VERSION "MFE24 Sensor Master v3 (ascii-safe)"

NS_ :

BS_:

BU_: Loadcells Accels FrontNode RearCAN RideHeight VehicleController

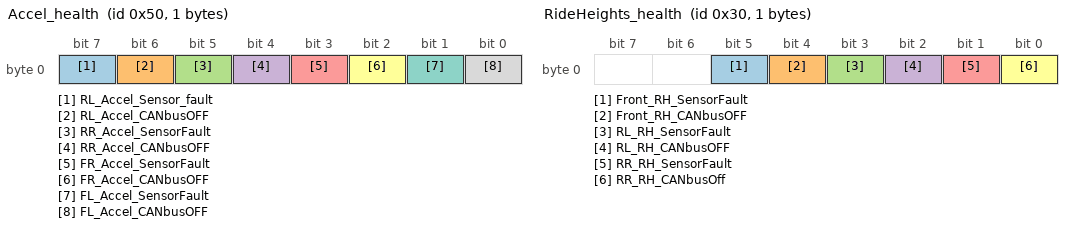
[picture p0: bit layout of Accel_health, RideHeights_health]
BO_ 80 Accel_health: 1 Accels
 SG_ RL_Accel_Sensor_fault : 7|1@1- (1,0) [0|0] "" Vector__XXX
 SG_ RL_Accel_CANbusOFF : 6|1@1- (1,0) [0|0] "" Vector__XXX
 SG_ RR_Accel_SensorFault : 5|1@1- (1,0) [0|0] "" Vector__XXX
 SG_ RR_Accel_CANbusOFF : 4|1@1- (1,0) [0|0] "" Vector__XXX
 SG_ FR_Accel_SensorFault : 3|1@1- (1,0) [0|0] "" Vector__XXX
 SG_ FR_Accel_CANbusOFF : 2|1@1- (1,0) [0|0] "" Vector__XXX
 SG_ FL_Accel_SensorFault : 1|1@1- (1,0) [0|0] "" Vector__XXX
 SG_ FL_Accel_CANbusOFF : 0|1@1- (1,0) [0|0] "" Vector__XXX

BO_ 48 RideHeights_health: 1 RideHeight
 SG_ Front_RH_SensorFault : 5|1@1- (1,0) [0|0] "" Vector__XXX
 SG_ Front_RH_CANbusOFF : 4|1@1- (1,0) [0|0] "" Vector__XXX
 SG_ RL_RH_SensorFault : 3|1@1- (1,0) [0|0] "" Vector__XXX
 SG_ RL_RH_CANbusOFF : 2|1@1- (1,0) [0|0] "" Vector__XXX
 SG_ RR_RH_SensorFault : 1|1@1- (1,0) [0|0] "" Vector__XXX
 SG_ RR_RH_CANbusOff : 0|1@1- (1,0) [0|0] "" Vector__XXX

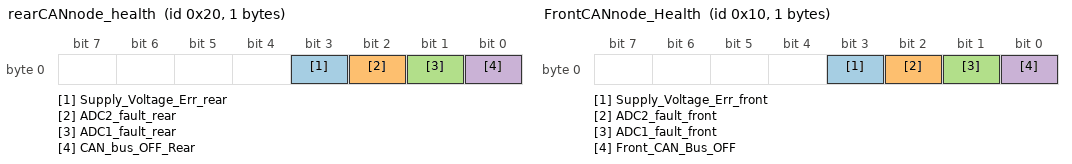
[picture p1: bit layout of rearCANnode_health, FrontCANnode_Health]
BO_ 32 rearCANnode_health: 1 RearCAN
 SG_ Supply_Voltage_Err_rear : 3|1@1- (1,0) [0|0] "" Vector__XXX
 SG_ ADC2_fault_rear : 2|1@1- (1,0) [0|0] "" Vector__XXX
 SG_ ADC1_fault_rear : 1|1@1- (1,0) [0|0] "" Vector__XXX
 SG_ CAN_bus_OFF_Rear : 0|1@1- (1,0) [0|0] "" Vector__XXX

BO_ 16 FrontCANnode_Health: 1 FrontNode
 SG_ Supply_Voltage_Err_front : 3|1@1- (1,0) [0|0] "" Vector__XXX
 SG_ ADC2_fault_front : 2|1@1- (1,0) [0|0] "" Vector__XXX
 SG_ ADC1_fault_front : 1|1@1- (1,0) [0|0] "" Vector__XXX
 SG_ Front_CAN_Bus_OFF : 0|1@1- (1,0) [0|0] "" Vector__XXX

BO_ 800 BrakeRotorTemps: 8 FrontNode
 SG_ BrakeTemp_FL : 0|16@1+ (0.1,0) [0|150] "degC" Vector__XXX
 SG_ BrakeTemp_FR : 16|16@1+ (0.1,0) [0|150] "degC" Vector__XXX

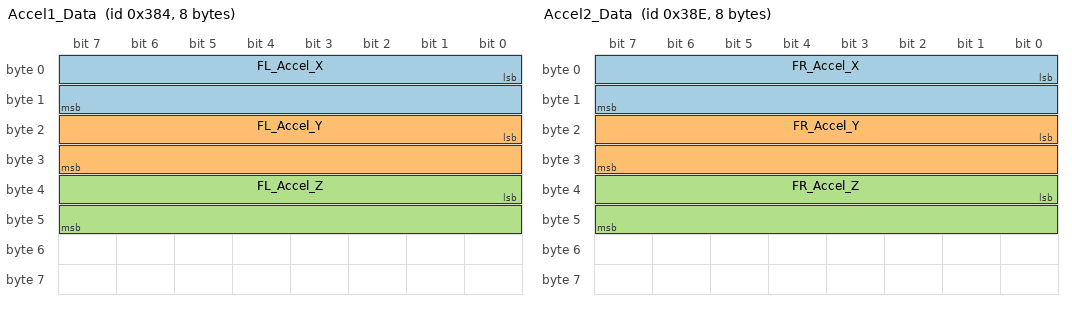
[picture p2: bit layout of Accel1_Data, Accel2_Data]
BO_ 900 Accel1_Data: 8 Accels
 SG_ FL_Accel_X : 0|16@1- (0.001,0) [-8|8] "g" Vector__XXX
 SG_ FL_Accel_Y : 16|16@1- (0.001,0) [-8|8] "g" Vector__XXX
 SG_ FL_Accel_Z : 32|16@1- (0.001,0) [-8|8] "g" Vector__XXX

BO_ 910 Accel2_Data: 8 Accels
 SG_ FR_Accel_X : 0|16@1- (0.001,0) [-8|8] "g" Vector__XXX
 SG_ FR_Accel_Y : 16|16@1- (0.001,0) [-8|8] "g" Vector__XXX
 SG_ FR_Accel_Z : 32|16@1- (0.001,0) [-8|8] "g" Vector__XXX

BO_ 700 OilTemps: 8 FrontNode
 SG_ OilTemp_Engine : 0|12@1+ (0.1,-40) [-40|170] "degC" Vector__XXX
 SG_ OilTemp_Gearbox : 12|12@1+ (0.1,-40) [-40|170] "degC" Vector__XXX

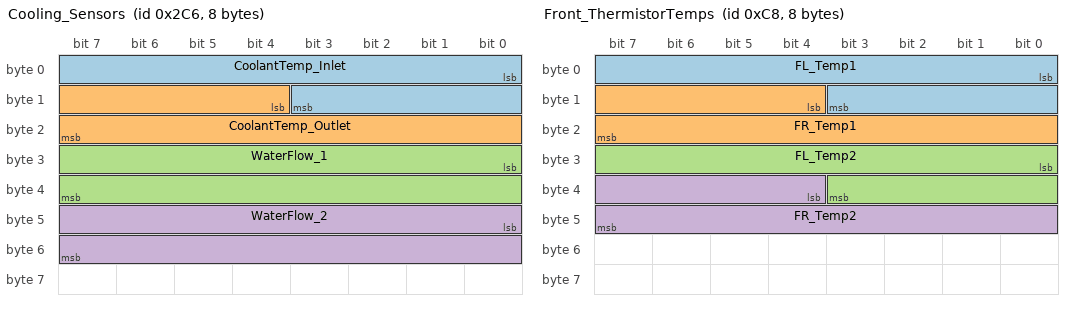
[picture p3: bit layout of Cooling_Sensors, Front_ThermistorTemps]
BO_ 710 Cooling_Sensors: 8 VehicleController
 SG_ CoolantTemp_Inlet : 0|12@1+ (0.1,-40) [-40|180] "degC" Vector__XXX
 SG_ CoolantTemp_Outlet : 12|12@1+ (0.1,-40) [-40|180] "degC" Vector__XXX
 SG_ WaterFlow_1 : 24|16@1+ (0.01,0) [0|25] "L/min" Vector__XXX
 SG_ WaterFlow_2 : 40|16@1+ (0.01,0) [0|25] "L/min" Vector__XXX

BO_ 100 FUTEK1_Load: 8 FrontNode
 SG_ Load1 : 0|16@1+ (0.1,0) [0|10000] "N" Vector__XXX

BO_ 110 FUTEK2_Load: 8 FrontNode
 SG_ Load2 : 0|16@1+ (0.1,0) [0|10000] "N" Vector__XXX

BO_ 200 Front_ThermistorTemps: 8 FrontNode
 SG_ FL_Temp1 : 0|12@1+ (0.1,-40) [-40|180] "degC" Vector__XXX
 SG_ FR_Temp1 : 12|12@1+ (0.1,-40) [-40|180] "degC" Vector__XXX
 SG_ FL_Temp2 : 24|12@1+ (0.1,-40) [-40|180] "degC" Vector__XXX
 SG_ FR_Temp2 : 36|12@1+ (0.1,-40) [-40|180] "degC" Vector__XXX

BO_ 300 Front_RotPotAngles: 8 FrontNode
 SG_ FR_Rotpot : 0|16@1+ (0.01,0) [0|90] "deg" Vector__XXX
 SG_ FL_Rotpot : 16|16@1+ (0.01,0) [0|90] "deg" Vector__XXX

BO_ 210 BrakeLineTemp_Front: 8 FrontNode
 SG_ BrakeLineTemp_Front : 0|16@1+ (0.1,-40) [-40|500] "degC" Vector__XXX

BO_ 400 Rear_LoadCells: 8 RearCAN
 SG_ Load1 : 0|16@1+ (0.1,0) [0|10000] "N" Vector__XXX
 SG_ Load2 : 16|16@1+ (0.1,0) [0|10000] "N" Vector__XXX

BO_ 500 Rear_RotPotAngles: 8 RearCAN
 SG_ RL_Rotpot : 0|16@1+ (0.01,0) [0|90] "deg" Vector__XXX
 SG_ RR_Rotpot : 16|16@1+ (0.01,0) [0|90] "deg" Vector__XXX

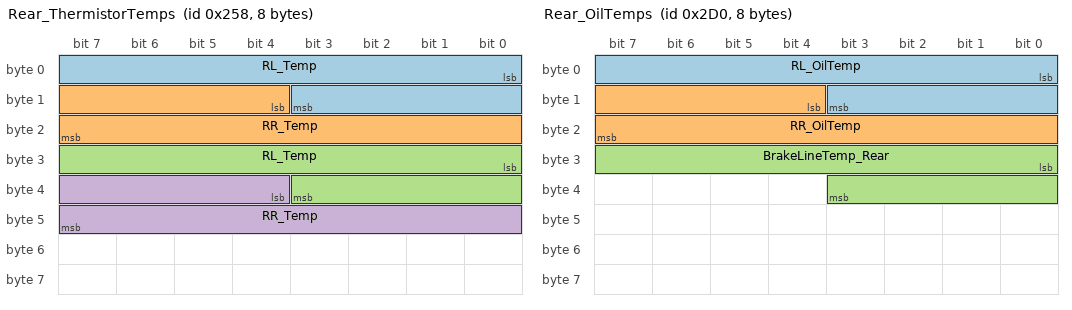
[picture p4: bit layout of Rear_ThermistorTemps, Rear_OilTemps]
BO_ 600 Rear_ThermistorTemps: 8 RearCAN
 SG_ RL_Temp : 0|12@1+ (0.1,-40) [-40|180] "degC" Vector__XXX
 SG_ RR_Temp : 12|12@1+ (0.1,-40) [-40|180] "degC" Vector__XXX
 SG_ RL_Temp : 24|12@1+ (0.1,-40) [-40|180] "degC" Vector__XXX
 SG_ RR_Temp : 36|12@1+ (0.1,-40) [-40|180] "degC" Vector__XXX

BO_ 720 Rear_OilTemps: 8 RearCAN
 SG_ RL_OilTemp : 0|12@1+ (0.1,-40) [-40|170] "degC" Vector__XXX
 SG_ RR_OilTemp : 12|12@1+ (0.1,-40) [-40|170] "degC" Vector__XXX
 SG_ BrakeLineTemp_Rear : 24|12@1+ (0.1,-40) [-40|500] "degC" Vector__XXX

BO_ 810 Rear_BrakeRotorTemp: 8 RearCAN
 SG_ BrakeTemp : 0|16@1+ (0.1,0) [0|150] "degC" Vector__XXX

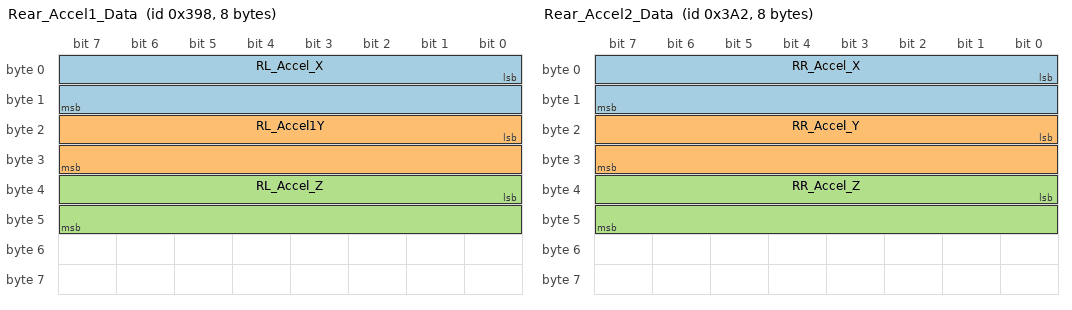
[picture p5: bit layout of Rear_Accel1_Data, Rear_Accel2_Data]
BO_ 920 Rear_Accel1_Data: 8 Accels
 SG_ RL_Accel_X : 0|16@1- (0.001,0) [-8|8] "g" Vector__XXX
 SG_ RL_Accel1Y : 16|16@1- (0.001,0) [-8|8] "g" Vector__XXX
 SG_ RL_Accel_Z : 32|16@1- (0.001,0) [-8|8] "g" Vector__XXX

BO_ 930 Rear_Accel2_Data: 8 Accels
 SG_ RR_Accel_X : 0|16@1- (0.001,0) [-8|8] "g" Vector__XXX
 SG_ RR_Accel_Y : 16|16@1- (0.001,0) [-8|8] "g" Vector__XXX
 SG_ RR_Accel_Z : 32|16@1- (0.001,0) [-8|8] "g" Vector__XXX

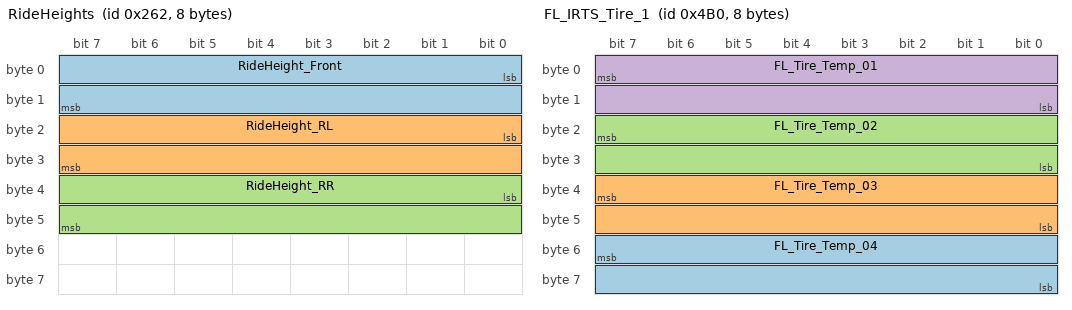
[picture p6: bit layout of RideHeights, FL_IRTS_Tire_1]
BO_ 610 RideHeights: 8 RideHeight
 SG_ RideHeight_Front : 0|16@1+ (1,0) [0|500] "mm" Vector__XXX
 SG_ RideHeight_RL : 16|16@1+ (1,0) [0|500] "mm" Vector__XXX
 SG_ RideHeight_RR : 32|16@1+ (1,0) [0|500] "mm" Vector__XXX

BO_ 1200 FL_IRTS_Tire_1: 8 Vector__XXX
 SG_ FL_Tire_Temp_04 : 55|16@0+ (0.1,-100) [-100|6453.5] "degC" Vector__XXX
 SG_ FL_Tire_Temp_03 : 39|16@0+ (0.1,-100) [-100|6453.5] "degC" Vector__XXX
 SG_ FL_Tire_Temp_02 : 23|16@0+ (0.1,-100) [-100|6453.5] "degC" Vector__XXX
 SG_ FL_Tire_Temp_01 : 7|16@0+ (0.1,-100) [-100|6453.5] "degC" Vector__XXX

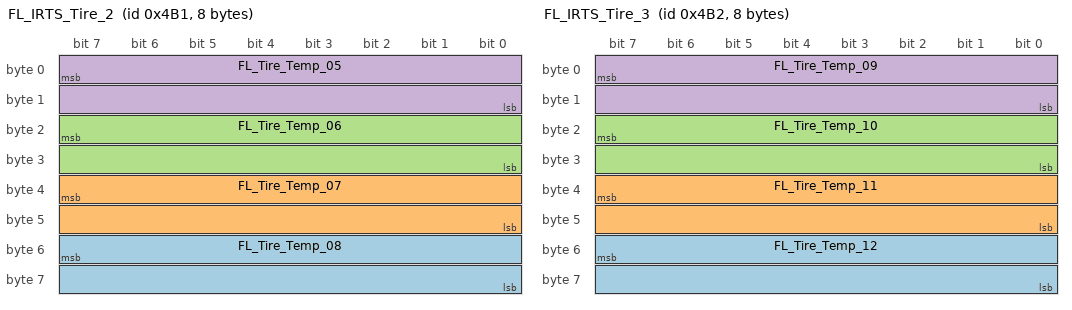
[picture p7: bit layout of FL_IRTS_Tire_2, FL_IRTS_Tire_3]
BO_ 1201 FL_IRTS_Tire_2: 8 Vector__XXX
 SG_ FL_Tire_Temp_08 : 55|16@0+ (0.1,-100) [-100|6453.5] "degC" Vector__XXX
 SG_ FL_Tire_Temp_07 : 39|16@0+ (0.1,-100) [-100|6453.5] "degC" Vector__XXX
 SG_ FL_Tire_Temp_06 : 23|16@0+ (0.1,-100) [-100|6453.5] "degC" Vector__XXX
 SG_ FL_Tire_Temp_05 : 7|16@0+ (0.1,-100) [-100|6453.5] "degC" Vector__XXX

BO_ 1202 FL_IRTS_Tire_3: 8 Vector__XXX
 SG_ FL_Tire_Temp_12 : 55|16@0+ (0.1,-100) [-100|6453.5] "degC" Vector__XXX
 SG_ FL_Tire_Temp_11 : 39|16@0+ (0.1,-100) [-100|6453.5] "degC" Vector__XXX
 SG_ FL_Tire_Temp_10 : 23|16@0+ (0.1,-100) [-100|6453.5] "degC" Vector__XXX
 SG_ FL_Tire_Temp_09 : 7|16@0+ (0.1,-100) [-100|6453.5] "degC" Vector__XXX

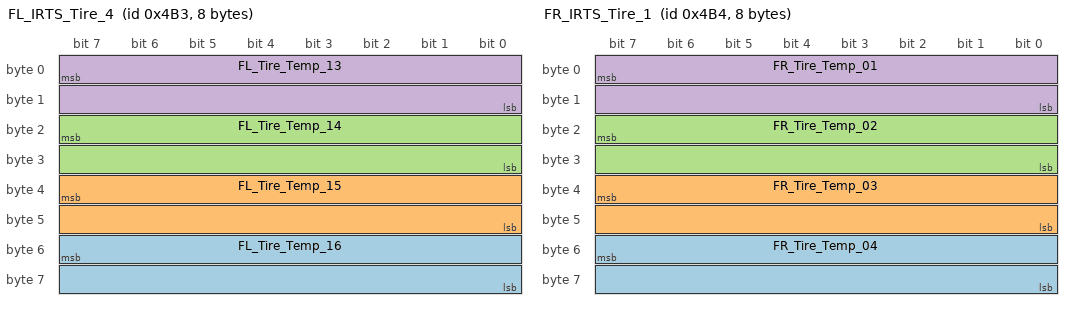
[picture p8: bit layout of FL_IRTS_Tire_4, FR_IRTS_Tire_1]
BO_ 1203 FL_IRTS_Tire_4: 8 Vector__XXX
 SG_ FL_Tire_Temp_16 : 55|16@0+ (0.1,-100) [-100|6453.5] "degC" Vector__XXX
 SG_ FL_Tire_Temp_15 : 39|16@0+ (0.1,-100) [-100|6453.5] "degC" Vector__XXX
 SG_ FL_Tire_Temp_14 : 23|16@0+ (0.1,-100) [-100|6453.5] "degC" Vector__XXX
 SG_ FL_Tire_Temp_13 : 7|16@0+ (0.1,-100) [-100|6453.5] "degC" Vector__XXX

BO_ 1204 FR_IRTS_Tire_1: 8 Vector__XXX
 SG_ FR_Tire_Temp_04 : 55|16@0+ (0.1,-100) [-100|6453.5] "degC" Vector__XXX
 SG_ FR_Tire_Temp_03 : 39|16@0+ (0.1,-100) [-100|6453.5] "degC" Vector__XXX
 SG_ FR_Tire_Temp_02 : 23|16@0+ (0.1,-100) [-100|6453.5] "degC" Vector__XXX
 SG_ FR_Tire_Temp_01 : 7|16@0+ (0.1,-100) [-100|6453.5] "degC" Vector__XXX

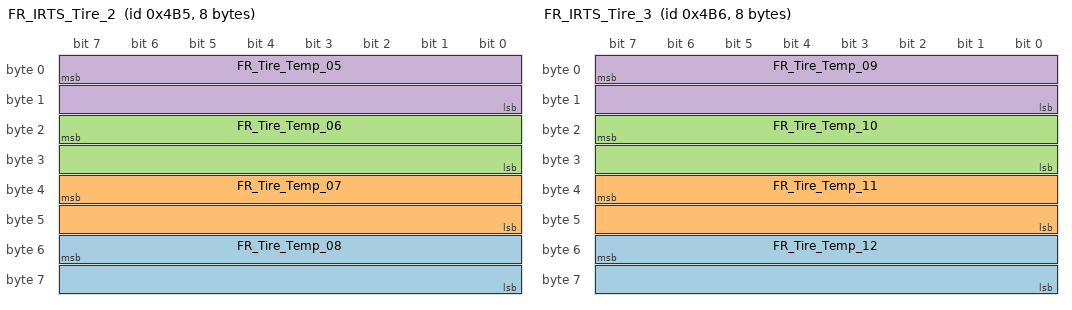
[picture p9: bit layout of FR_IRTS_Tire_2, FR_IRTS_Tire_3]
BO_ 1205 FR_IRTS_Tire_2: 8 Vector__XXX
 SG_ FR_Tire_Temp_08 : 55|16@0+ (0.1,-100) [-100|6453.5] "degC" Vector__XXX
 SG_ FR_Tire_Temp_07 : 39|16@0+ (0.1,-100) [-100|6453.5] "degC" Vector__XXX
 SG_ FR_Tire_Temp_06 : 23|16@0+ (0.1,-100) [-100|6453.5] "degC" Vector__XXX
 SG_ FR_Tire_Temp_05 : 7|16@0+ (0.1,-100) [-100|6453.5] "degC" Vector__XXX

BO_ 1206 FR_IRTS_Tire_3: 8 Vector__XXX
 SG_ FR_Tire_Temp_12 : 55|16@0+ (0.1,-100) [-100|6453.5] "degC" Vector__XXX
 SG_ FR_Tire_Temp_11 : 39|16@0+ (0.1,-100) [-100|6453.5] "degC" Vector__XXX
 SG_ FR_Tire_Temp_10 : 23|16@0+ (0.1,-100) [-100|6453.5] "degC" Vector__XXX
 SG_ FR_Tire_Temp_09 : 7|16@0+ (0.1,-100) [-100|6453.5] "degC" Vector__XXX

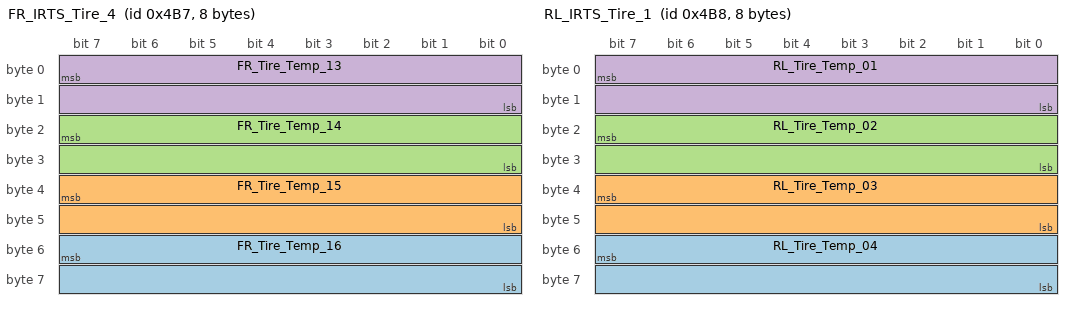
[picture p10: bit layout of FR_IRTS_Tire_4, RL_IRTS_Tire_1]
BO_ 1207 FR_IRTS_Tire_4: 8 Vector__XXX
 SG_ FR_Tire_Temp_16 : 55|16@0+ (0.1,-100) [-100|6453.5] "degC" Vector__XXX
 SG_ FR_Tire_Temp_15 : 39|16@0+ (0.1,-100) [-100|6453.5] "degC" Vector__XXX
 SG_ FR_Tire_Temp_14 : 23|16@0+ (0.1,-100) [-100|6453.5] "degC" Vector__XXX
 SG_ FR_Tire_Temp_13 : 7|16@0+ (0.1,-100) [-100|6453.5] "degC" Vector__XXX

BO_ 1208 RL_IRTS_Tire_1: 8 Vector__XXX
 SG_ RL_Tire_Temp_04 : 55|16@0+ (0.1,-100) [-100|6453.5] "degC" Vector__XXX
 SG_ RL_Tire_Temp_03 : 39|16@0+ (0.1,-100) [-100|6453.5] "degC" Vector__XXX
 SG_ RL_Tire_Temp_02 : 23|16@0+ (0.1,-100) [-100|6453.5] "degC" Vector__XXX
 SG_ RL_Tire_Temp_01 : 7|16@0+ (0.1,-100) [-100|6453.5] "degC" Vector__XXX

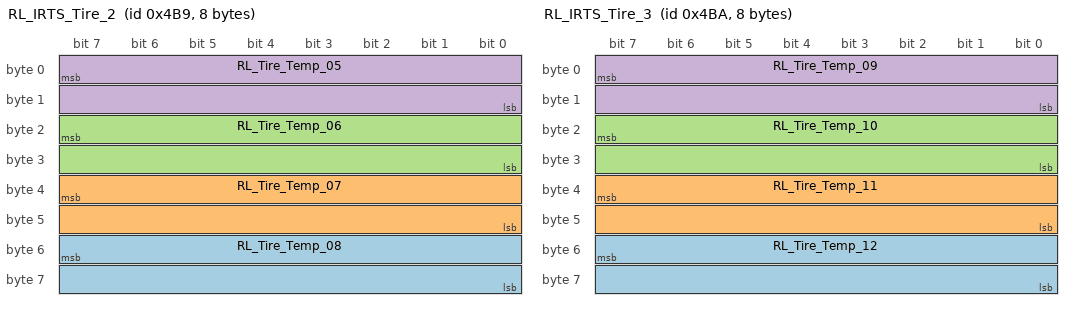
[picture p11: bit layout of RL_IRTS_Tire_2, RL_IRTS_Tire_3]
BO_ 1209 RL_IRTS_Tire_2: 8 Vector__XXX
 SG_ RL_Tire_Temp_08 : 55|16@0+ (0.1,-100) [-100|6453.5] "degC" Vector__XXX
 SG_ RL_Tire_Temp_07 : 39|16@0+ (0.1,-100) [-100|6453.5] "degC" Vector__XXX
 SG_ RL_Tire_Temp_06 : 23|16@0+ (0.1,-100) [-100|6453.5] "degC" Vector__XXX
 SG_ RL_Tire_Temp_05 : 7|16@0+ (0.1,-100) [-100|6453.5] "degC" Vector__XXX

BO_ 1210 RL_IRTS_Tire_3: 8 Vector__XXX
 SG_ RL_Tire_Temp_12 : 55|16@0+ (0.1,-100) [-100|6453.5] "degC" Vector__XXX
 SG_ RL_Tire_Temp_11 : 39|16@0+ (0.1,-100) [-100|6453.5] "degC" Vector__XXX
 SG_ RL_Tire_Temp_10 : 23|16@0+ (0.1,-100) [-100|6453.5] "degC" Vector__XXX
 SG_ RL_Tire_Temp_09 : 7|16@0+ (0.1,-100) [-100|6453.5] "degC" Vector__XXX

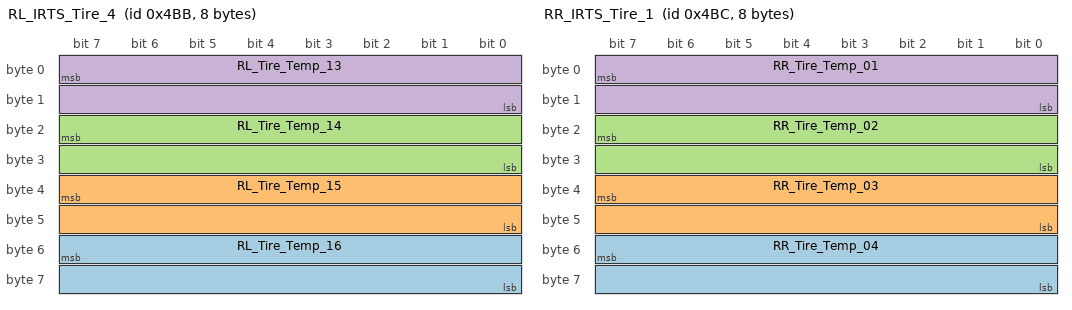
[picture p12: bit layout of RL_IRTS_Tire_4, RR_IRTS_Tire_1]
BO_ 1211 RL_IRTS_Tire_4: 8 Vector__XXX
 SG_ RL_Tire_Temp_16 : 55|16@0+ (0.1,-100) [-100|6453.5] "degC" Vector__XXX
 SG_ RL_Tire_Temp_15 : 39|16@0+ (0.1,-100) [-100|6453.5] "degC" Vector__XXX
 SG_ RL_Tire_Temp_14 : 23|16@0+ (0.1,-100) [-100|6453.5] "degC" Vector__XXX
 SG_ RL_Tire_Temp_13 : 7|16@0+ (0.1,-100) [-100|6453.5] "degC" Vector__XXX

BO_ 1212 RR_IRTS_Tire_1: 8 Vector__XXX
 SG_ RR_Tire_Temp_04 : 55|16@0+ (0.1,-100) [-100|6453.5] "degC" Vector__XXX
 SG_ RR_Tire_Temp_03 : 39|16@0+ (0.1,-100) [-100|6453.5] "degC" Vector__XXX
 SG_ RR_Tire_Temp_02 : 23|16@0+ (0.1,-100) [-100|6453.5] "degC" Vector__XXX
 SG_ RR_Tire_Temp_01 : 7|16@0+ (0.1,-100) [-100|6453.5] "degC" Vector__XXX

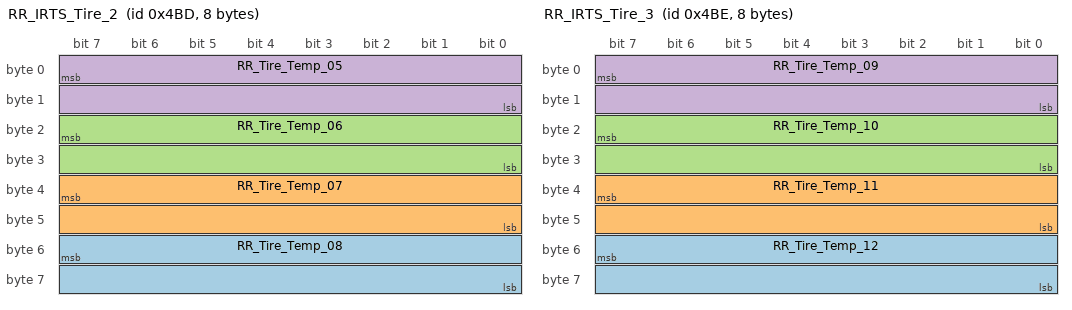
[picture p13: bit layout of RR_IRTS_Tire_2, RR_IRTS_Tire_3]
BO_ 1213 RR_IRTS_Tire_2: 8 Vector__XXX
 SG_ RR_Tire_Temp_08 : 55|16@0+ (0.1,-100) [-100|6453.5] "degC" Vector__XXX
 SG_ RR_Tire_Temp_07 : 39|16@0+ (0.1,-100) [-100|6453.5] "degC" Vector__XXX
 SG_ RR_Tire_Temp_06 : 23|16@0+ (0.1,-100) [-100|6453.5] "degC" Vector__XXX
 SG_ RR_Tire_Temp_05 : 7|16@0+ (0.1,-100) [-100|6453.5] "degC" Vector__XXX

BO_ 1214 RR_IRTS_Tire_3: 8 Vector__XXX
 SG_ RR_Tire_Temp_12 : 55|16@0+ (0.1,-100) [-100|6453.5] "degC" Vector__XXX
 SG_ RR_Tire_Temp_11 : 39|16@0+ (0.1,-100) [-100|6453.5] "degC" Vector__XXX
 SG_ RR_Tire_Temp_10 : 23|16@0+ (0.1,-100) [-100|6453.5] "degC" Vector__XXX
 SG_ RR_Tire_Temp_09 : 7|16@0+ (0.1,-100) [-100|6453.5] "degC" Vector__XXX

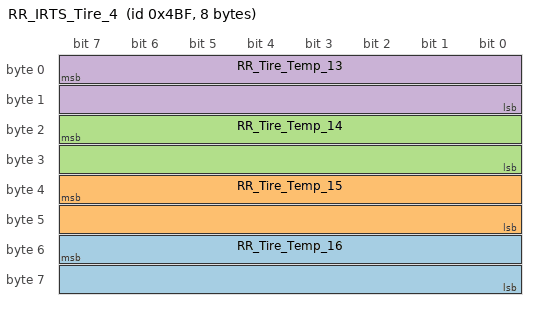
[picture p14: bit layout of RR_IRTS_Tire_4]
BO_ 1215 RR_IRTS_Tire_4: 8 Vector__XXX
 SG_ RR_Tire_Temp_16 : 55|16@0+ (0.1,-100) [-100|6453.5] "degC" Vector__XXX
 SG_ RR_Tire_Temp_15 : 39|16@0+ (0.1,-100) [-100|6453.5] "degC" Vector__XXX
 SG_ RR_Tire_Temp_14 : 23|16@0+ (0.1,-100) [-100|6453.5] "degC" Vector__XXX
 SG_ RR_Tire_Temp_13 : 7|16@0+ (0.1,-100) [-100|6453.5] "degC" Vector__XXX
